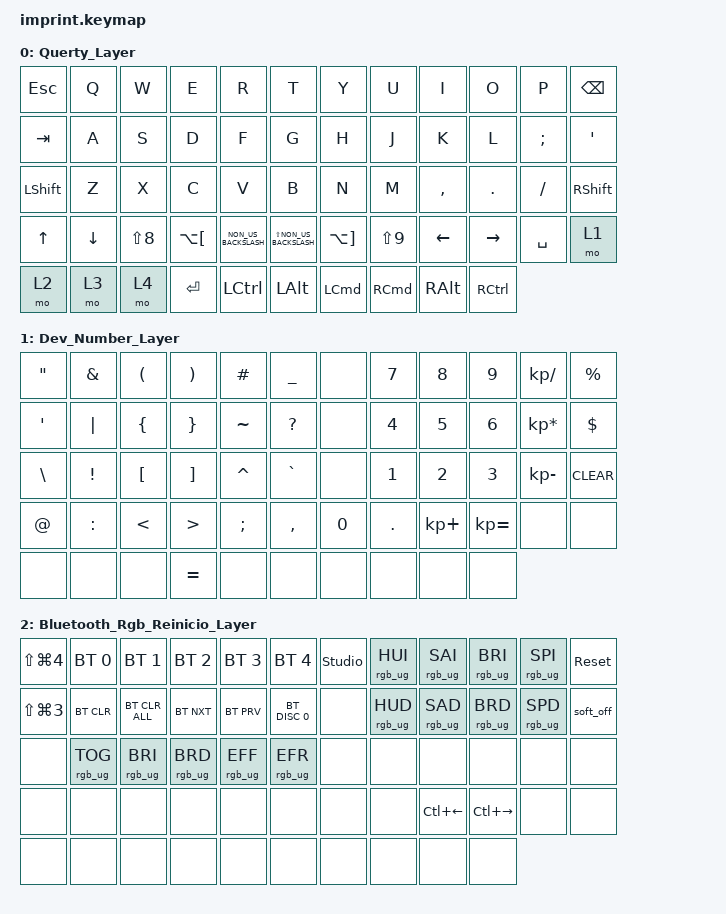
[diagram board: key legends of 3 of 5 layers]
#include <input/processors.dtsi>
#include <dt-bindings/zmk/input_transform.h>
#include <behaviors.dtsi>
#include <dt-bindings/zmk/bt.h>
#include <dt-bindings/zmk/keys.h>
#include <dt-bindings/zmk/pointing.h>
#include <dt-bindings/zmk/rgb.h>

/ {
    chosen { zmk,matrix-transform = &imprint_letters_only_full_bottom_row; };

    keymap {
        compatible = "zmk,keymap";

        Querty_Layer {
            bindings = <
&kp ESCAPE    &kp Q     &kp W       &kp E         &kp R                 &kp T                         &kp Y             &kp U              &kp I           &kp O              &kp P      &kp BACKSPACE
&kp TAB       &kp A     &kp S       &kp D         &kp F                 &kp G                         &kp H             &kp J              &kp K           &kp L              &kp SEMI   &kp SQT
&kp LSHFT     &kp Z     &kp X       &kp C         &kp V                 &kp B                         &kp N             &kp M              &kp COMMA       &kp DOT            &kp FSLH   &kp RSHFT
&kp UP_ARROW  &kp DOWN  &kp LS(N8)  &kp LA(LBKT)  &kp NON_US_BACKSLASH  &kp LS(NON_US_BACKSLASH)      &kp LA(RBKT)      &kp LS(N9)         &kp LEFT_ARROW  &kp RIGHT          &kp SPACE  &mo 1
&mo 2         &mo 3     &mo 4       &kp ENTER     &kp LEFT_CONTROL      &kp LEFT_ALT                  &kp LEFT_COMMAND  &kp RIGHT_COMMAND  &kp RIGHT_ALT   &kp RIGHT_CONTROL
            >;
        };

        Dev_Number_Layer {
            bindings = <
&kp DOUBLE_QUOTES  &kp AMPERSAND    &kp LEFT_PARENTHESIS  &kp RIGHT_PARENTHESIS  &kp HASH       &kp UNDERSCORE      &none   &kp N7        &kp N8       &kp N9        &kp KP_DIVIDE    &kp PERCENT
&kp SQT            &kp PIPE         &kp LEFT_BRACE        &kp RIGHT_BRACE        &kp TILDE      &kp QUESTION        &none   &kp NUMBER_4  &kp N5       &kp NUMBER_6  &kp KP_MULTIPLY  &kp DOLLAR
&kp BACKSLASH      &kp EXCLAMATION  &kp LEFT_BRACKET      &kp RIGHT_BRACKET      &kp CARET      &kp GRAVE           &none   &kp N1        &kp N2       &kp N3        &kp KP_MINUS     &kp CLEAR
&kp AT_SIGN        &kp COLON        &kp LESS_THAN         &kp GREATER_THAN       &kp SEMICOLON  &kp COMMA           &kp N0  &kp DOT       &kp KP_PLUS  &kp KP_EQUAL  &none            &none
&none              &none            &none                 &kp EQUAL              &none          &none               &none   &none         &none        &none
            >;
        };

        Bluetooth_Rgb_Reinicio_Layer {
            bindings = <
&kp LS(LG(NUMBER_4))  &bt BT_SEL 0     &bt BT_SEL 1     &bt BT_SEL 2     &bt BT_SEL 3     &bt BT_SEL 4         &studio_unlock  &rgb_ug RGB_HUI  &rgb_ug RGB_SAI  &rgb_ug RGB_BRI  &rgb_ug RGB_SPI  &sys_reset
&kp LS(LG(NUMBER_3))  &bt BT_CLR       &bt BT_CLR_ALL   &bt BT_NXT       &bt BT_PRV       &bt BT_DISC 0        &none           &rgb_ug RGB_HUD  &rgb_ug RGB_SAD  &rgb_ug RGB_BRD  &rgb_ug RGB_SPD  &soft_off
&none                 &rgb_ug RGB_TOG  &rgb_ug RGB_BRI  &rgb_ug RGB_BRD  &rgb_ug RGB_EFF  &rgb_ug RGB_EFR      &none           &none            &none            &none            &none            &none
&none                 &none            &none            &none            &none            &none                &none           &none            &kp LC(LEFT)     &kp LC(RIGHT)    &none            &none
&none                 &none            &none            &none            &none            &none                &none           &none            &none            &none
            >;
        };

        Auto_Mouse_Layer {
            bindings = <
&trans  &trans  &trans  &trans    &trans  &trans         &trans     &trans     &trans     &trans  &trans    &trans
&trans  &trans  &trans  &trans    &trans  &trans         &trans     &trans     &trans     &trans  &trans    &trans
&trans  &trans  &trans  &trans    &trans  &trans         &trans     &trans     &trans     &trans  &trans    &trans
&trans  &trans  &trans  &trans    &trans  &trans         &trans     &trans     &trans     &trans  &mkp MB4  &trans
&trans  &trans  &trans  &mkp MB5  &trans  &mkp LCLK      &mkp MCLK  &mkp MCLK  &mkp RCLK  &trans  &trans    &trans
            >;
        };

        F_Layer {
            bindings = <
&kp F1           &kp F2             &kp F3  &kp F4            &kp F5  &kp F6            &kp F7  &kp F8  &kp F9      &kp F10     &kp F11   &kp F12
&trans           &trans             &trans  &trans            &trans  &trans            &trans  &trans  &trans      &trans      &trans    &trans
&trans           &trans             &trans  &trans            &trans  &trans            &trans  &trans  &trans      &trans      &trans    &trans
&kp C_VOLUME_UP  &kp C_VOLUME_DOWN  &trans  &trans            &trans  &trans            &trans  &trans  &kp C_PREV  &kp C_NEXT  &kp C_PP  &trans
&trans           &trans             &trans  &kp C_PLAY_PAUSE  &trans  &trans            &trans  &trans  &trans      &trans      &trans    &trans
&trans           &trans             &trans  &trans            &trans                            &trans  &trans      &trans      &trans    &trans
                                                              &trans  &trans  &trans    &trans  &trans  &trans
                                                              &trans  &trans  &trans    &trans  &trans  &trans
            >;
        };
    };
};

// right hand trackball configuration
// &trackball_peripheral_listener {
//    input-processors =
//     // activate layer 3 within 500ms of the trackball moving
//     <&zip_temp_layer 3 500>;
// };
// left hand trackball configuration

&trackball_central_listener {
    input-processors =
        // multiply sensitivity by 1, divide by 3 (make it slower for scrolling),,,,,,,,,,,,,,
        <&zip_xy_scaler 1 3>,
        // make this trackball output scrolling events by default instead of cursor movement,,,,,,,,,,,,,,
        <&zip_xy_to_scroll_mapper>,
        // invert vertical scrolling so that the view moves in the same direction as the top of the trackball,,,,,,,,,,,,,,
        <&zip_scroll_transform INPUT_TRANSFORM_Y_INVERT>;
};
